# AM335x register map
Vendor: Texas Instruments; Series: Sitara AM335x; File version: 1.1
CPU: Cortex-A8 r0p0, little endian
Registers are 32-bit, read-write, reset 0x0 unless marked. A register's access mark holds for its fields unless they carry their own. Offsets are from the block's base; [hi:lo] are bit positions; {n}, {i} and the like mark numbered series; 'fields as' and 'values as' point back to an identical list.

## DDR23mPHY — DDR PHY Control Registers
Base 0x44E12000
{0x1C+0x34*i} CMD{i}_CTRL_SLAVE_RATIO_0 (i=0..2) — CSR0 Register
  [9:0] CMD_SLAVE_RATIO wo — Ratio value for address/command launch timing in DDR PHY macro. This is the fraction of a
{0x28+0x34*i} CMD{i}_DLL_LOCK_DIFF_0 (i=0..2) — DLD0 Register
  [3:0] DLL_LOCK_DIFF wo — The max number of delay line taps variation allowed while maintaining the master DLL lock.This is
{0x2C+0x34*i} CMD{i}_INVERT_CLKOUT_0 (i=0..2) — ICLK0 Register
  [0] INVERT_CLK_SEL — bit: 0 (W) Inverts the polarity of DRAM clock.
0xC8 DATA0_RD_DQS_SLAVE_RATIO_0 — RDQSSR0 Register
  [9:0] RD_DQS_SLAVE_RATIO_CS0 wo — Ratio value for Read DQS slave DLL for CS0.
0xDC DATA0_WR_DQS_SLAVE_RATIO_0 — WDQSSR0 Register
  [9:0] WR_DQS_SLAVE_RATIO_CS0 wo — Ratio value for Write DQS slave DLL for CS0.
0xF0 DATA0_WRLVL_INIT_RATIO_0 — MWRLVLINI_RATIO Register
  [9:0] WRLVL_INIT_RATIO_CS0 wo — The user programmable init ratio used by Write Leveling FSM when
0xF8 DATA0_WRLVL_INIT_MODE_0 — MWRLVLINI_MODE Register
  [0] WRLVL_INIT_MODE_SEL — bit: 0 (W) The user programmable init ratio selection mode for Write Leveling FSM.
0xFC DATA0_GATELVL_INIT_RATIO_0 — DQSGTI_RATIO Register
  [9:0] GATELVL_INIT_RATIO_CS0 wo — The user programmable init ratio used by DQS Gate Training FSM when
0x104 DATA0_GATELVL_INIT_MODE_0 — DQS_GTI_MODE Register
  [0] GATELVL_INIT_MODE_SEL — bit: 0 (W) User programmable init ratio selection mode for DQS Gate Training FSM.
0x108 DATA0_FIFO_WE_SLAVE_RATIO_0 — DQS_GS_RATIO Register
  [9:0] FIFO_WE_SLAVE_RATIO_CS0 wo — Ratio value for fifo we for CS0.
0x11C DATA0_DQ_OFFSET_0 — DQS_T_DQ_OFFSET Register
  [6:0] OFFSET — Default value 40 equates to a 90 degree shift.
0x120 DATA0_WR_DATA_SLAVE_RATIO_0 — WDS_RATIO Register
  [9:0] WR_DATA_SLAVE_RATIO_CS0 wo — Ratio value for write data slave DLL for CS0.
0x134 DATA0_USE_RANK0_DELAYS — DELAY_SEL Register
  [0] RANK0_DELAY — bit: 0 (W) Delay Selection
0x138 DATA0_DLL_LOCK_DIFF_0 — DLL_LOCK_DIFF Register
  fields as CMD0_DLL_LOCK_DIFF_0
0x16C DATA1_RD_DQS_SLAVE_RATIO_0 — RDQSSR0 Register
  fields as DATA0_RD_DQS_SLAVE_RATIO_0
0x180 DATA1_WR_DQS_SLAVE_RATIO_0 — WDQSSR0 Register
  fields as DATA0_WR_DQS_SLAVE_RATIO_0
0x194 DATA1_WRLVL_INIT_RATIO_0 — MWRLVLINI_RATIO Register
  fields as DATA0_WRLVL_INIT_RATIO_0
0x19C DATA1_WRLVL_INIT_MODE_0 — MWRLVLINI_MODE Register
  fields as DATA0_WRLVL_INIT_MODE_0
0x1A0 DATA1_GATELVL_INIT_RATIO_0 — DQSGTI_RATIO Register
  fields as DATA0_GATELVL_INIT_RATIO_0
0x1A8 DATA1_GATELVL_INIT_MODE_0 — DQS_GTI_MODE Register
  fields as DATA0_GATELVL_INIT_MODE_0
0x1AC DATA1_FIFO_WE_SLAVE_RATIO_0 — DQS_GS_RATIO Register
  [9:0] FIFO_WE_SLAVE_RATIO_CS0 wo — Ratio value for fifo we for CS0.
0x1C0 DATA1_DQ_OFFSET_0 — DQS_T_DQ_OFFSET Register
  [6:0] OFFSET — Default value 40 equates to a 90 degree shift.
0x1C4 DATA1_WR_DATA_SLAVE_RATIO_0 — WDS_RATIO Register
  fields as DATA0_WR_DATA_SLAVE_RATIO_0
0x1D8 DATA1_USE_RANK0_DELAYS — DELAY_SEL Register
  [0] RANK0_DELAY — bit: 0 (W) Delay Selection
0x1DC DATA1_DLL_LOCK_DIFF_0 — DLL_LOCK_DIFF Register
  fields as CMD0_DLL_LOCK_DIFF_0

## CM_CEFUSE — Clock Module - CEFUSE
Base 0x44E00A00
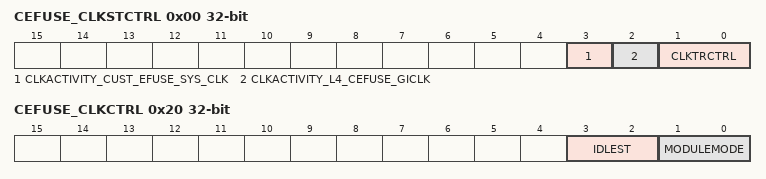
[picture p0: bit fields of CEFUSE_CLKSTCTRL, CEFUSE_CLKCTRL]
0x00 CEFUSE_CLKSTCTRL
  [3] CLKACTIVITY_CUST_EFUSE_SYS_CLK — bit: 9 (R)This field indicates the state of the Cust_Efuse_SYSCLK clock input of the domain.[0x0 = Inact; 0x1 = Act]
  [2] CLKACTIVITY_L4_CEFUSE_GICLK — bit: 8 (R)This field indicates the state of the L4_CEFUSE_GCLK clock input of the domain.[0x0 = Inact; 0x1 = Act]
  [1:0] CLKTRCTRL — bit: 0,1 (RW)Clock state transition [see e_PRCM_CLKTRCTRL]
0x20 CEFUSE_CLKCTRL — CM_CLKCTRL Register
  [3:2] IDLEST — bit: 16,17 (R)Module idle status.[see e_PRCM_IDLEST]
  [1:0] MODULEMODE — bit: 0,1 (RW)Control the way mandatory clocks are managed.[see e_PRCM_MODULEMODE]
